# R7FA8M1AH register map
Vendor: Renesas; Series: RA8; File version: 1.2
CPU: CM85 r0p0, little endian, MPU, FPU, VTOR, 4 interrupt priority bits
Registers are 32-bit, read-write, reset 0x0 unless marked. A register's access mark holds for its fields unless they carry their own. Offsets are from the block's base; [hi:lo] are bit positions; 'fields as' and 'values as' point back to an identical list.

## I3C (part 2 of 4) — I2C I3C unified IP
Base 0x4035F000
Same registers: I3C_NS 0x5035F000
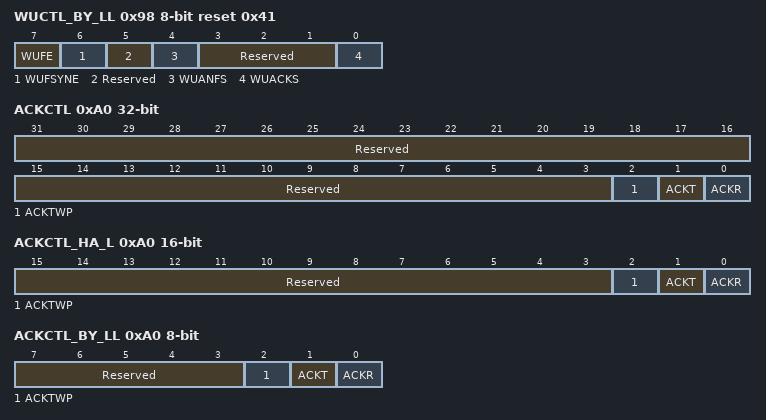
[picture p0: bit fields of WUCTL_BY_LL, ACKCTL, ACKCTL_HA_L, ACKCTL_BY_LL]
0x98 WUCTL_BY_LL 8-bit reset 0x41 — Wake Up Unit Control Register
  [7] WUFE — Wake Up function Enable
    0=Wake-up function disables; 1=Wake-up function enables
  [6] WUFSYNE — Wake-Up function Synchronous Enable
    0=This IP asynchronous circuit enable; 1=This IP synchronous circuit enable
  [5] Reserved — This bit is read as 0. The write value should be 0.
  [4] WUANFS — Wake-Up Analog Noise Filter Selection
    0=Do not add the Wake Up analog filter; 1=Add the Wake Up analog filter
  [3:1] Reserved — These bits are read as 000. The write value should be 000.
  [0] WUACKS — Wake-Up Acknowledge Selection
0xA0 ACKCTL — Acknowledge Control Register
  [31:3] Reserved — These bits are read as 00000000000000000000000000000. The write value should be 00000000000000000000000000000.
  [2] ACKTWP wo — ACKT Write Protect
    0=The ACKT bit are protected; 1=The ACKT bit can be written (When writing simultaneously with the value of the target bit)
  [1] ACKT read-modifies — Acknowledge Transmission
    0=A 0 is sent as the acknowledge bit (ACK transmission); 1=A 1 is sent as the acknowledge bit (NACK transmission)
  [0] ACKR ro — Acknowledge Reception
    0=A 0 is received as the acknowledge bit (ACK reception); 1=A 1 is received as the acknowledge bit (NACK reception)
0xA0 ACKCTL_HA_L 16-bit — Acknowledge Control Register
  [15:3] Reserved — These bits are read as 0000000000000. The write value should be 0000000000000.
  [2] ACKTWP wo — ACKT Write Protect
    values as ACKCTL.ACKTWP
  [1] ACKT read-modifies — Acknowledge Transmission
    values as ACKCTL.ACKT
  [0] ACKR ro — Acknowledge Reception
    values as ACKCTL.ACKR
0xA0 ACKCTL_BY_LL 8-bit — Acknowledge Control Register
  [7:3] Reserved — These bits are read as 00000. The write value should be 00000.
  [2] ACKTWP wo — ACKT Write Protect
    values as ACKCTL.ACKTWP
  [1] ACKT read-modifies — Acknowledge Transmission
    values as ACKCTL.ACKT
  [0] ACKR ro — Acknowledge Reception
    values as ACKCTL.ACKR
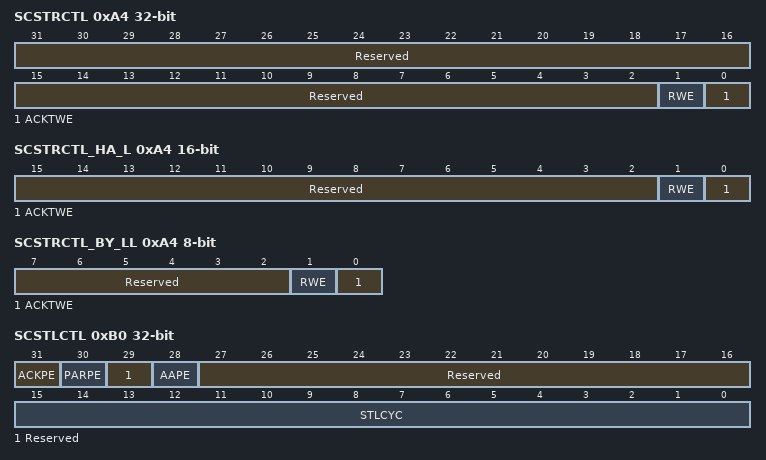
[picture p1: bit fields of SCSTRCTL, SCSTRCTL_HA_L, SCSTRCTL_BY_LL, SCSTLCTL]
0xA4 SCSTRCTL — SCL Stretch Control Register
  [31:2] Reserved — These bits are read as 000000000000000000000000000000. The write value should be 000000000000000000000000000000.
  [1] RWE — Receive Wait Enable
    0=No WAIT (The period between ninth clock cycle and first clock cycle is not held low.); 1=WAIT (The period between ninth clock cycle and first clock cycle is held low.)
  [0] ACKTWE — Acknowledge Transmission Wait Enabl (*1)
    0=NTST.RDBFF0 is set at the rising edge of the ninth SCL clock cycle; 1=NTST.RDBFF0 is set at the rising edge of the eighth SCL clock cycle
0xA4 SCSTRCTL_HA_L 16-bit — SCL Stretch Control Register
  [15:2] Reserved — These bits are read as 00000000000000. The write value should be 00000000000000.
  [1] RWE — Receive Wait Enable
    values as SCSTRCTL.RWE
  [0] ACKTWE — Acknowledge Transmission Wait Enabl (*1)
    values as SCSTRCTL.ACKTWE
0xA4 SCSTRCTL_BY_LL 8-bit — SCL Stretch Control Register
  [7:2] Reserved — These bits are read as 000000. The write value should be 000000.
  [1] RWE — Receive Wait Enable
    values as SCSTRCTL.RWE
  [0] ACKTWE — Acknowledge Transmission Wait Enabl (*1)
    values as SCSTRCTL.ACKTWE
0xB0 SCSTLCTL — SCL Stalling Control Register
  [31] ACKPE — ACK phase EnableStall enable bit during ACK/NACK phase
    0=Does not stall the SCL clock during the ACK/NACK phase; 1=Stall the SCL clock during the ACK/NACK phase
  [30] PARPE — Parity Phase EnableStall enable bit in parity bit period
    0=Does not stall the SCL clock during the parity bit period; 1=Stall the SCL clock during the parity bit period
  [29] Reserved — This bit is read as 0. The write value should be 0.
  [28] AAPE — Assigend Address Phase EnableEnable bit that allows stall by the first bit at address assignment
    0=Does not stall the SCL clock during the address assignment phase; 1=Stall the SCL clock during the parity bit period address assignment phase
  [27:16] Reserved — These bits are read as 000000000000. The write value should be 000000000000.
  [15:0] STLCYC — Stalling Cycle
0xB0 SCSTLCTL_HA_L 16-bit — SCL Stalling Control Register
  [15:0] STLCYC — Stalling Cycle
0xB0 SCSTLCTL_BY_LL 8-bit — SCL Stalling Control Register
  [7:0] STLCYC — Stalling Cycle
0xB1 SCSTLCTL_BY_LH 8-bit — SCL Stalling Control Register
  [7:0] STLCYC — Stalling Cycle
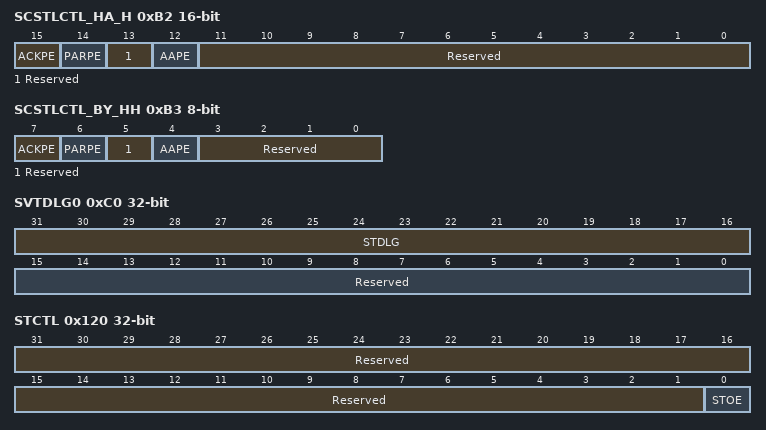
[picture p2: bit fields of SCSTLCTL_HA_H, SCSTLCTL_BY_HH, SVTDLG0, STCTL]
0xB2 SCSTLCTL_HA_H 16-bit — SCL Stalling Control Register
  [15] ACKPE — ACK phase EnableStall enable bit during ACK/NACK phase
    values as SCSTLCTL.ACKPE
  [14] PARPE — Parity Phase EnableStall enable bit in parity bit period
    values as SCSTLCTL.PARPE
  [13] Reserved — This bit is read as 0. The write value should be 0.
  [12] AAPE — Assigend Address Phase EnableEnable bit that allows stall by the first bit at address assignment
    values as SCSTLCTL.AAPE
  [11:0] Reserved — These bits are read as 000000000000. The write value should be 000000000000.
0xB3 SCSTLCTL_BY_HH 8-bit — SCL Stalling Control Register
  [7] ACKPE — ACK phase EnableStall enable bit during ACK/NACK phase
    values as SCSTLCTL.ACKPE
  [6] PARPE — Parity Phase EnableStall enable bit in parity bit period
    values as SCSTLCTL.PARPE
  [5] Reserved — This bit is read as 0. The write value should be 0.
  [4] AAPE — Assigend Address Phase EnableEnable bit that allows stall by the first bit at address assignment
    values as SCSTLCTL.AAPE
  [3:0] Reserved — These bits are read as 0000. The write value should be 0000.
0xC0 SVTDLG0 — Slave Transfer Data Length Register 0
  [31:16] STDLG — Slave Transfer Data Length
  [15:0] Reserved — These bits are read as 0000000000000000. The write value should be 0000000000000000.
0xC2 SVTDLG0_HA_H 16-bit — Slave Transfer Data Length Register 0
  [15:0] STDLG — Slave Transfer Data Length
0xC2 SVTDLG0_BY_HL 8-bit — Slave Transfer Data Length Register 0
  [7:0] STDLG — Slave Transfer Data Length
0xC3 SVTDLG0_BY_HH 8-bit — Slave Transfer Data Length Register 0
  [7:0] STDLG — Slave Transfer Data Length
0x120 STCTL read-modifies — Synchronous Timiming Control Register
  [31:1] Reserved — These bits are read as 0000000000000000000000000000000. The write value should be 0000000000000000000000000000000.
  [0] STOE read-modifies — Synchronous Timing output Enable
    0=Disable; 1=Enable
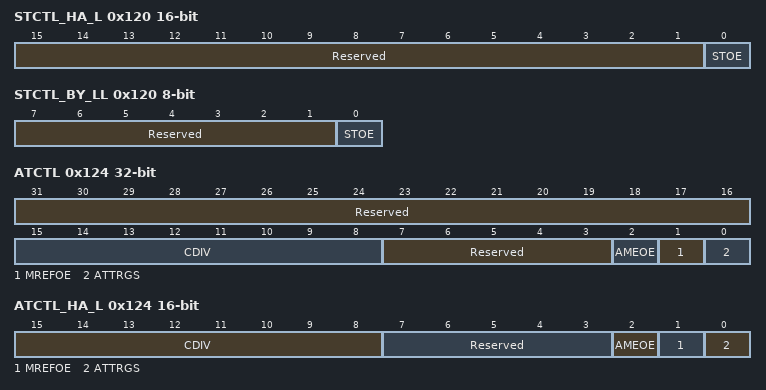
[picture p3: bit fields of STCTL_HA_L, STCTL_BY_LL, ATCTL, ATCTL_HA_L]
0x120 STCTL_HA_L 16-bit read-modifies — Synchronous Timiming Control Register
  [15:1] Reserved — These bits are read as 000000000000000. The write value should be 000000000000000.
  [0] STOE read-modifies — Synchronous Timing output Enable
    0=Disable; 1=Enable
0x120 STCTL_BY_LL 8-bit read-modifies — Synchronous Timiming Control Register
  [7:1] Reserved — These bits are read as 0000000. The write value should be 0000000.
  [0] STOE read-modifies — Synchronous Timing output Enable
    0=Disable; 1=Enable
0x124 ATCTL — Asynchronous Timimg Control Register
  [31:16] Reserved — These bits are read as 0000000000000000. The write value should be 0000000000000000.
  [15:8] CDIV — TCLK Counter Divide Setting
  [7:3] Reserved — These bits are read as 00000. The write value should be 00000.
  [2] AMEOE — Additional Master-initiated bus Event Output Enable
    0=Disable; 1=Enable
  [1] MREFOE — MREF Output Enable (Capture Event / Counter Overflow)
    0=Disable; 1=Enable
  [0] ATTRGS — Asynchronous Timing Trigger Select
    0=Software Trigger; 1=Hardware Trigger
0x124 ATCTL_HA_L 16-bit — Asynchronous Timimg Control Register
  [15:8] CDIV — TCLK Counter Divide Setting
  [7:3] Reserved — These bits are read as 00000. The write value should be 00000.
  [2] AMEOE — Additional Master-initiated bus Event Output Enable
    0=Disable; 1=Enable
  [1] MREFOE — MREF Output Enable (Capture Event / Counter Overflow)
    0=Disable; 1=Enable
  [0] ATTRGS — Asynchronous Timing Trigger Select
    0=Software Trigger; 1=Hardware Trigger
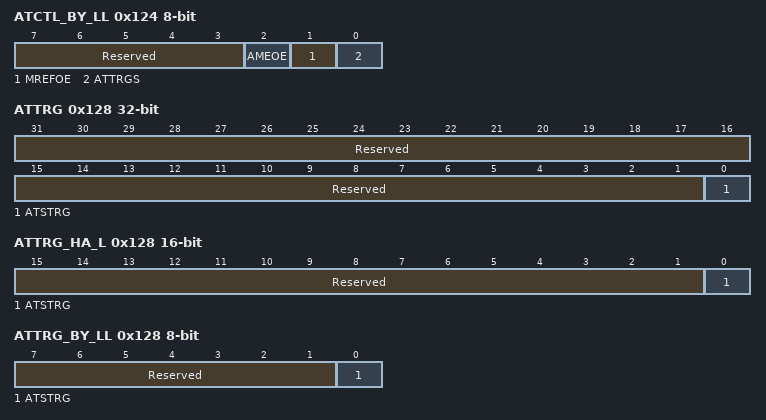
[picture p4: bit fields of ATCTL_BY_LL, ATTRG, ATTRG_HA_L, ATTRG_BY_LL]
0x124 ATCTL_BY_LL 8-bit — Asynchronous Timimg Control Register
  [7:3] Reserved — These bits are read as 00000. The write value should be 00000.
  [2] AMEOE — Additional Master-initiated bus Event Output Enable
    0=Disable; 1=Enable
  [1] MREFOE — MREF Output Enable (Capture Event / Counter Overflow)
    0=Disable; 1=Enable
  [0] ATTRGS — Asynchronous Timing Trigger Select
    0=Software Trigger; 1=Hardware Trigger
0x125 ATCTL_BY_LH 8-bit — Asynchronous Timimg Control Register
  [7:0] CDIV — TCLK Counter Divide Setting
0x128 ATTRG wo — Asynchronous Timiming Trigger Register
  [31:1] Reserved — The write value should be 0000000000000000000000000000000.
  [0] ATSTRG — Asynchronous Timing Software Trigger
    0=Write : do nothing; 1=Write : Software trigger (one-shot pulse) output
0x128 ATTRG_HA_L 16-bit wo — Asynchronous Timiming Trigger Register
  [15:1] Reserved — The write value should be 000000000000000.
  [0] ATSTRG — Asynchronous Timing Software Trigger
    values as ATTRG.ATSTRG
0x128 ATTRG_BY_LL 8-bit wo — Asynchronous Timiming Trigger Register
  [7:1] Reserved — The write value should be 0000000.
  [0] ATSTRG — Asynchronous Timing Software Trigger
    values as ATTRG.ATSTRG
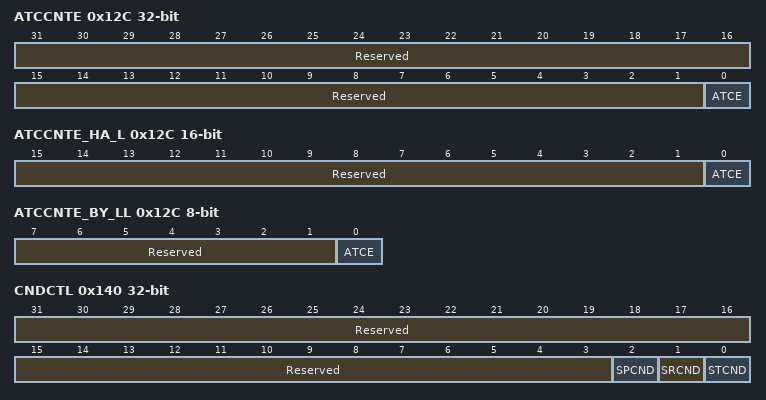
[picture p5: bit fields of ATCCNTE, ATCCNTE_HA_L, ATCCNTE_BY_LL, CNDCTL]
0x12C ATCCNTE — Asynchronous Timing Contorol Counter enable Register
  [31:1] Reserved — These bits are read as 0000000000000000000000000000000. The write value should be 0000000000000000000000000000000.
  [0] ATCE — Asynchronous Timing Counter Enable for MREF, MC2, SC1, SC2.
    0=Disable; 1=Enable
0x12C ATCCNTE_HA_L 16-bit — Asynchronous Timing Contorol Counter enable Register
  [15:1] Reserved — These bits are read as 000000000000000. The write value should be 000000000000000.
  [0] ATCE — Asynchronous Timing Counter Enable for MREF, MC2, SC1, SC2.
    0=Disable; 1=Enable
0x12C ATCCNTE_BY_LL 8-bit — Asynchronous Timing Contorol Counter enable Register
  [7:1] Reserved — These bits are read as 0000000. The write value should be 0000000.
  [0] ATCE — Asynchronous Timing Counter Enable for MREF, MC2, SC1, SC2.
    0=Disable; 1=Enable
0x140 CNDCTL — Condition Control Register
  [31:3] Reserved — These bits are read as 00000000000000000000000000000. The write value should be 00000000000000000000000000000.
  [2] SPCND read-modifies — STOP (P) Condition Issuance
    0=Does not request to issue a STOP condition; 1=Requests to issue a STOP condition
  [1] SRCND read-modifies — Repeated START (Sr) Condition Issuance
    0=Does not request to issue a Repeated START condition; 1=Requests to issue a Repeated START condition
  [0] STCND read-modifies — START (S) Condition Issuance
    0=Does not request to issue a START condition; 1=Requests to issue a START condition
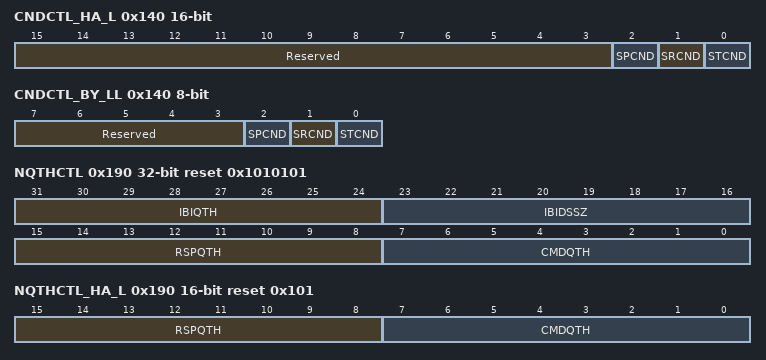
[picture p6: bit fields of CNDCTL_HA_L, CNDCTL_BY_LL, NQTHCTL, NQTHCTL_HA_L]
0x140 CNDCTL_HA_L 16-bit — Condition Control Register
  [15:3] Reserved — These bits are read as 0000000000000. The write value should be 0000000000000.
  [2] SPCND read-modifies — STOP (P) Condition Issuance
    values as CNDCTL.SPCND
  [1] SRCND read-modifies — Repeated START (Sr) Condition Issuance
    values as CNDCTL.SRCND
  [0] STCND read-modifies — START (S) Condition Issuance
    values as CNDCTL.STCND
0x140 CNDCTL_BY_LL 8-bit — Condition Control Register
  [7:3] Reserved — These bits are read as 00000. The write value should be 00000.
  [2] SPCND read-modifies — STOP (P) Condition Issuance
    values as CNDCTL.SPCND
  [1] SRCND read-modifies — Repeated START (Sr) Condition Issuance
    values as CNDCTL.SRCND
  [0] STCND read-modifies — START (S) Condition Issuance
    values as CNDCTL.STCND
0x150 NCMDQP wo — Normal Command Queue Port Register
  [31:0] NCMDQP — Normal Command Queue Port
0x154 NRSPQP ro read-modifies — Normal Response Queue Port Register
  [31:0] NRSPQP read-modifies — Normal Response Queue Port
0x158 NTDTBP0 read-modifies — Normal Transfer Data Buffer Port Register 0
  [31:0] NTDTBP0 read-modifies — Normal Transfer Data Buffer Port
0x158 NTDTBP0_BY_LL 8-bit read-modifies — Normal Transfer Data Buffer Port Register 0
  [7:0] NTDTBP0 read-modifies — Normal Transfer Data Buffer Port
0x17C NIBIQP read-modifies — Normal IBI Queue Port Register
  [31:0] NIBIQP read-modifies — Normal IBI Queue Port
0x180 NRSQP ro read-modifies — Normal Receive Status Queue Port Register
  [31:0] NRSQP read-modifies — Normal Receive Status Queue Port
0x184 HCMDQP wo — High Priority Command Queue Port Register
  [31:0] HCMDQP — High Priority Command Queue Port
0x188 HRSPQP ro read-modifies — High Priority Response Queue Port Register
  [31:0] HRSPQP read-modifies — High Priority Response Queue Port
0x18C HTDTBP read-modifies — High Priority Transfer Data Buffer Port Register
  [31:0] HTDTBP read-modifies — High Priority Transfer Data Buffer Port
0x190 NQTHCTL reset 0x1010101 — Normal Queue Threshold Control Register
  [31:24] IBIQTH — Normal IBI Queue Threshold
    0=Interrupt is generated when the Outstanding IBI Status count is >= 1; 0=Interrupt is issued when IBI Data Buffer is completely empty
  [23:16] IBIDSSZ — Normal IBI Data Segment Size
  [15:8] RSPQTH — Normal Response Queue Threshold
    0=Interrupt is issued when response Queue contains 1 entry (DWORD)
  [7:0] CMDQTH — Normal Command Queue Threshold
    0=Interrupt is issued when Command Queue is completely empty
0x190 NQTHCTL_HA_L 16-bit reset 0x101 — Normal Queue Threshold Control Register
  [15:8] RSPQTH — Normal Response Queue Threshold
    values as NQTHCTL.RSPQTH
  [7:0] CMDQTH — Normal Command Queue Threshold
    0=Interrupt is issued when Command Queue is completely empty
0x190 NQTHCTL_BY_LL 8-bit reset 0x1 — Normal Queue Threshold Control Register
  [7:0] CMDQTH — Normal Command Queue Threshold
    0=Interrupt is issued when Command Queue is completely empty
0x191 NQTHCTL_BY_LH 8-bit reset 0x1 — Normal Queue Threshold Control Register
  [7:0] RSPQTH — Normal Response Queue Threshold
    values as NQTHCTL.RSPQTH
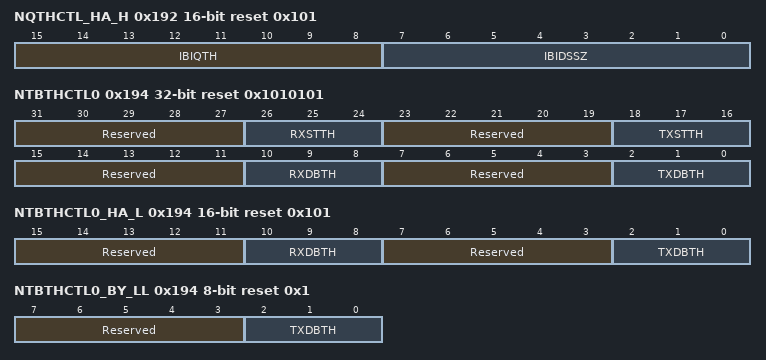
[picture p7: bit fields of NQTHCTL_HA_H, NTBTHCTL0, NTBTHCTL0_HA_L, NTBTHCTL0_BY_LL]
0x192 NQTHCTL_HA_H 16-bit reset 0x101 — Normal Queue Threshold Control Register
  [15:8] IBIQTH — Normal IBI Queue Threshold
    values as NQTHCTL.IBIQTH
  [7:0] IBIDSSZ — Normal IBI Data Segment Size
0x192 NQTHCTL_BY_HL 8-bit reset 0x1 — Normal Queue Threshold Control Register
  [7:0] IBIDSSZ — Normal IBI Data Segment Size
0x193 NQTHCTL_BY_HH 8-bit reset 0x1 — Normal Queue Threshold Control Register
  [7:0] IBIQTH — Normal IBI Queue Threshold
    values as NQTHCTL.IBIQTH
0x194 NTBTHCTL0 reset 0x1010101 — Normal Transfer Data Buffer Threshold Control Register 0
  [31:27] Reserved — These bits are read as 00000. The write value should be 00000.
  [26:24] RXSTTH — Normal Rx Start Threshold
    0=Wait for 2 empty DWORDs; 1=Wait for 4 empty DWORDs; 2=Wait for 8 empty DWORDs; 3=Wait for 16 empty DWORDs; 4=Wait for 32 empty DWORDs; 5=Wait for 64 empty DWORDs; 6=Wait for 128 empty DWORDs; 7=Wait for 256 empty DWORDs
  [23:19] Reserved — These bits are read as 00000. The write value should be 00000.
  [18:16] TXSTTH — Normal Tx Start Threshold
    0=Wait for 2 entry DWORDs; 1=Wait for 4 entry DWORDs; 2=Wait for 8 entry DWORDs; 3=Wait for 16 entry DWORDs; 4=Wait for 32 entry DWORDs; 5=Wait for 64 entry DWORDs; 6=Wait for 128 entry DWORDs; 7=Wait for 256 entry DWORDs
  [15:11] Reserved — These bits are read as 00000. The write value should be 00000.
  [10:8] RXDBTH — Normal Rx Data Buffer Threshold
    0=Interrupt triggers at 2 Rx Buffer entries, DWORDs; 1=Interrupt triggers at 4 Rx Buffer entries, DWORDs; 2=Interrupt triggers at 8 Rx Buffer entries, DWORDs; 3=Interrupt triggers at 16 Rx Buffer entries, DWORDs; 4=Interrupt triggers at 32 Rx Buffer entries, DWORDs; 5=Interrupt triggers at 64 Rx Buffer entries, DWORDs; 6=Interrupt triggers at 128 Rx Buffer entries, DWORDs; 7=Interrupt triggers at 256 Rx Buffer entries, DWORDs
  [7:3] Reserved — These bits are read as 00000. The write value should be 00000.
  [2:0] TXDBTH — Normal Tx Data Buffer Threshold
    0=Interrupt triggers at 2 Tx Buffer entries, DWORDs; 1=Interrupt triggers at 4 Tx Buffer entries, DWORDs; 2=Interrupt triggers at 8 Tx Buffer entries, DWORDs; 3=Interrupt triggers at 16 Tx Buffer entries, DWORDs; 4=Interrupt triggers at 32 Tx Buffer entries, DWORDs; 5=Interrupt triggers at 64 Tx Buffer entries, DWORDs; 6=Interrupt triggers at 128 Tx Buffer entries, DWORDs; 7=Interrupt triggers at 256 Tx Buffer entries, DWORDs
0x194 NTBTHCTL0_HA_L 16-bit reset 0x101 — Normal Transfer Data Buffer Threshold Control Register 0
  [15:11] Reserved — These bits are read as 00000. The write value should be 00000.
  [10:8] RXDBTH — Normal Rx Data Buffer Threshold
    values as NTBTHCTL0.RXDBTH
  [7:3] Reserved — These bits are read as 00000. The write value should be 00000.
  [2:0] TXDBTH — Normal Tx Data Buffer Threshold
    values as NTBTHCTL0.TXDBTH
0x194 NTBTHCTL0_BY_LL 8-bit reset 0x1 — Normal Transfer Data Buffer Threshold Control Register 0
  [7:3] Reserved — These bits are read as 00000. The write value should be 00000.
  [2:0] TXDBTH — Normal Tx Data Buffer Threshold
    values as NTBTHCTL0.TXDBTH
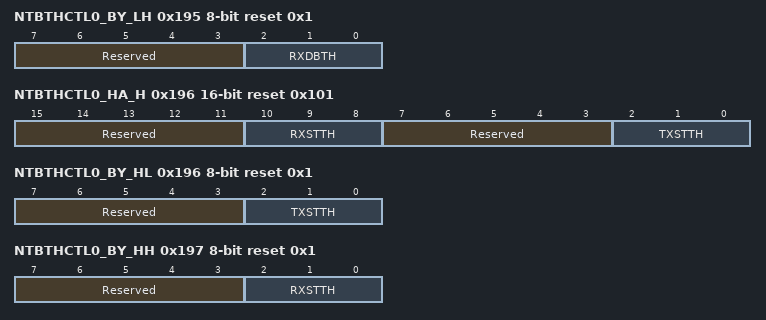
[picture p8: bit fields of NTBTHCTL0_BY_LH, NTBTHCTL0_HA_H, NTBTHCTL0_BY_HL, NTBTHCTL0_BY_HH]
0x195 NTBTHCTL0_BY_LH 8-bit reset 0x1 — Normal Transfer Data Buffer Threshold Control Register 0
  [7:3] Reserved — These bits are read as 00000. The write value should be 00000.
  [2:0] RXDBTH — Normal Rx Data Buffer Threshold
    values as NTBTHCTL0.RXDBTH
0x196 NTBTHCTL0_HA_H 16-bit reset 0x101 — Normal Transfer Data Buffer Threshold Control Register 0
  [15:11] Reserved — These bits are read as 00000. The write value should be 00000.
  [10:8] RXSTTH — Normal Rx Start Threshold
    values as NTBTHCTL0.RXSTTH
  [7:3] Reserved — These bits are read as 00000. The write value should be 00000.
  [2:0] TXSTTH — Normal Tx Start Threshold
    values as NTBTHCTL0.TXSTTH
0x196 NTBTHCTL0_BY_HL 8-bit reset 0x1 — Normal Transfer Data Buffer Threshold Control Register 0
  [7:3] Reserved — These bits are read as 00000. The write value should be 00000.
  [2:0] TXSTTH — Normal Tx Start Threshold
    values as NTBTHCTL0.TXSTTH
0x197 NTBTHCTL0_BY_HH 8-bit reset 0x1 — Normal Transfer Data Buffer Threshold Control Register 0
  [7:3] Reserved — These bits are read as 00000. The write value should be 00000.
  [2:0] RXSTTH — Normal Rx Start Threshold
    values as NTBTHCTL0.RXSTTH
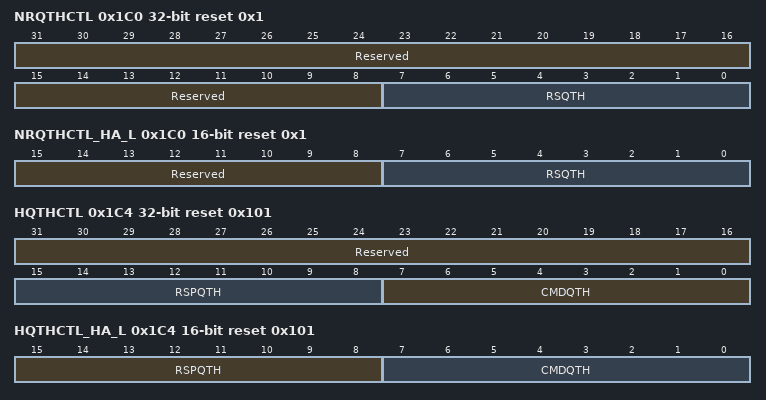
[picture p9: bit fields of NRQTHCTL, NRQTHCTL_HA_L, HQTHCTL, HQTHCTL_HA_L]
0x1C0 NRQTHCTL reset 0x1 — Normal Receive Status Queue Threshold Control Register
  [31:8] Reserved — These bits are read as 000000000000000000000000. The write value should be 000000000000000000000000.
  [7:0] RSQTH — Normal Receive Status Queue Threshold
    0=Interrupt is issued when Receive Status Queue contains 1 entry (DWORD)
0x1C0 NRQTHCTL_HA_L 16-bit reset 0x1 — Normal Receive Status Queue Threshold Control Register
  [15:8] Reserved — These bits are read as 00000000. The write value should be 00000000.
  [7:0] RSQTH — Normal Receive Status Queue Threshold
    values as NRQTHCTL.RSQTH
0x1C0 NRQTHCTL_BY_LL 8-bit reset 0x1 — Normal Receive Status Queue Threshold Control Register
  [7:0] RSQTH — Normal Receive Status Queue Threshold
    values as NRQTHCTL.RSQTH
0x1C4 HQTHCTL reset 0x101 — High Priority Queue Threshold Control Register
  [31:16] Reserved — These bits are read as 0000000000000000. The write value should be 0000000000000000.
  [15:8] RSPQTH — High Priority Response Queue Threshold
    0=Interrupt is issued when High Priority Response Queue contains 1 entry (DWORD)
  [7:0] CMDQTH — High Priority Command Queue Threshold
    0=Interrupt is issued when High Priority Command Queue is completely empty
0x1C4 HQTHCTL_HA_L 16-bit reset 0x101 — High Priority Queue Threshold Control Register
  [15:8] RSPQTH — High Priority Response Queue Threshold
    values as HQTHCTL.RSPQTH
  [7:0] CMDQTH — High Priority Command Queue Threshold
    values as HQTHCTL.CMDQTH
0x1C4 HQTHCTL_BY_LL 8-bit reset 0x1 — High Priority Queue Threshold Control Register
  [7:0] CMDQTH — High Priority Command Queue Threshold
    values as HQTHCTL.CMDQTH
0x1C5 HQTHCTL_BY_LH 8-bit reset 0x1 — High Priority Queue Threshold Control Register
  [7:0] RSPQTH — High Priority Response Queue Threshold
    values as HQTHCTL.RSPQTH
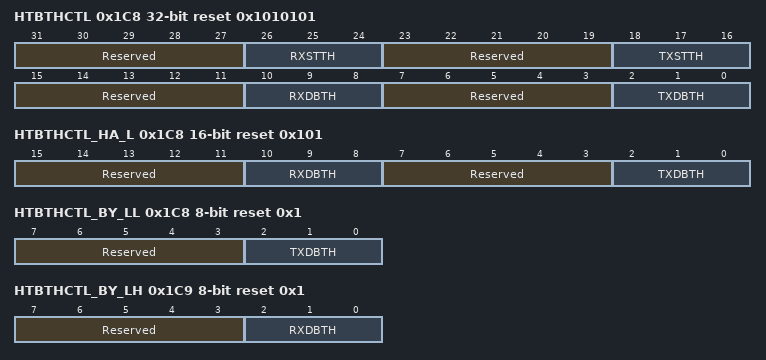
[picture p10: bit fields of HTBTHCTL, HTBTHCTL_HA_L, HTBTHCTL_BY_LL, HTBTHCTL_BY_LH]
0x1C8 HTBTHCTL reset 0x1010101 — High Priority Transfer Data Buffer Threshold Control Register
  [31:27] Reserved — These bits are read as 00000. The write value should be 00000.
  [26:24] RXSTTH — High Priority Rx Start Threshold
    values as NTBTHCTL0.RXSTTH
  [23:19] Reserved — These bits are read as 00000. The write value should be 00000.
  [18:16] TXSTTH — High Priority Tx Start Threshold
    values as NTBTHCTL0.TXSTTH
  [15:11] Reserved — These bits are read as 00000. The write value should be 00000.
  [10:8] RXDBTH — High Priority Rx Data Buffer Threshold
    0=Interrupt triggers at 2 High Priority Rx Buffer entries, DWORDs; 1=Interrupt triggers at 4 High Priority Rx Buffer entries, DWORDs; 2=Interrupt triggers at 8 High Priority Rx Buffer entries, DWORDs; 3=Interrupt triggers at 16 High Priority Rx Buffer entries, DWORDs; 4=Interrupt triggers at 32 High Priority Rx Buffer entries, DWORDs; 5=Interrupt triggers at 64 High Priority Rx Buffer entries, DWORDs; 6=Interrupt triggers at 128 High Priority Rx Buffer entries, DWORDs; 7=Interrupt triggers at 256 High Priority Rx Buffer entries, DWORDs
  [7:3] Reserved — These bits are read as 00000. The write value should be 00000.
  [2:0] TXDBTH — High Priority Tx Data Buffer Threshold
    0=Interrupt triggers at 2 High Priority Tx Buffer empties, DWORDs; 1=Interrupt triggers at 4 High Priority Tx Buffer empties, DWORDs; 2=Interrupt triggers at 8 High Priority Tx Buffer empties, DWORDs; 3=Interrupt triggers at 16 High Priority Tx Buffer empties, DWORDs; 4=Interrupt triggers at 32 High Priority Tx Buffer empties, DWORDs; 5=Interrupt triggers at 64 High Priority Tx Buffer empties, DWORDs; 6=Interrupt triggers at 128 High Priority Tx Buffer empties, DWORDs; 7=Interrupt triggers at 256 High Priority Tx Buffer empties, DWORDs
0x1C8 HTBTHCTL_HA_L 16-bit reset 0x101 — High Priority Transfer Data Buffer Threshold Control Register
  [15:11] Reserved — These bits are read as 00000. The write value should be 00000.
  [10:8] RXDBTH — High Priority Rx Data Buffer Threshold
    values as HTBTHCTL.RXDBTH
  [7:3] Reserved — These bits are read as 00000. The write value should be 00000.
  [2:0] TXDBTH — High Priority Tx Data Buffer Threshold
    values as HTBTHCTL.TXDBTH
0x1C8 HTBTHCTL_BY_LL 8-bit reset 0x1 — High Priority Transfer Data Buffer Threshold Control Register
  [7:3] Reserved — These bits are read as 00000. The write value should be 00000.
  [2:0] TXDBTH — High Priority Tx Data Buffer Threshold
    values as HTBTHCTL.TXDBTH
0x1C9 HTBTHCTL_BY_LH 8-bit reset 0x1 — High Priority Transfer Data Buffer Threshold Control Register
  [7:3] Reserved — These bits are read as 00000. The write value should be 00000.
  [2:0] RXDBTH — High Priority Rx Data Buffer Threshold
    values as HTBTHCTL.RXDBTH
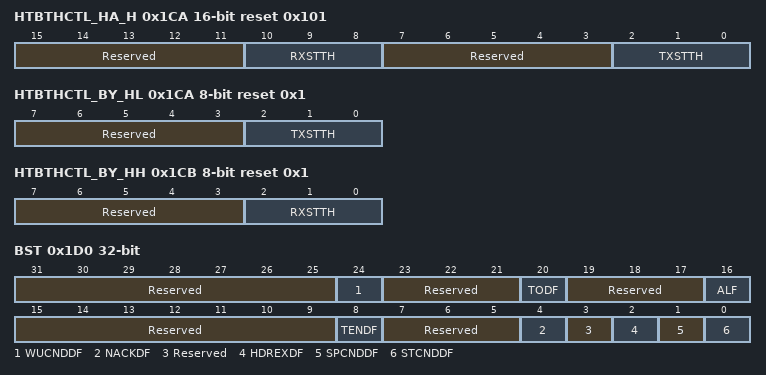
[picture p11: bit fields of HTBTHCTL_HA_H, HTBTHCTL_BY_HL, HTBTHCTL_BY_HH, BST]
0x1CA HTBTHCTL_HA_H 16-bit reset 0x101 — High Priority Transfer Data Buffer Threshold Control Register
  [15:11] Reserved — These bits are read as 00000. The write value should be 00000.
  [10:8] RXSTTH — High Priority Rx Start Threshold
    values as NTBTHCTL0.RXSTTH
  [7:3] Reserved — These bits are read as 00000. The write value should be 00000.
  [2:0] TXSTTH — High Priority Tx Start Threshold
    values as NTBTHCTL0.TXSTTH
0x1CA HTBTHCTL_BY_HL 8-bit reset 0x1 — High Priority Transfer Data Buffer Threshold Control Register
  [7:3] Reserved — These bits are read as 00000. The write value should be 00000.
  [2:0] TXSTTH — High Priority Tx Start Threshold
    values as NTBTHCTL0.TXSTTH
0x1CB HTBTHCTL_BY_HH 8-bit reset 0x1 — High Priority Transfer Data Buffer Threshold Control Register
  [7:3] Reserved — These bits are read as 00000. The write value should be 00000.
  [2:0] RXSTTH — High Priority Rx Start Threshold
    values as NTBTHCTL0.RXSTTH
0x1D0 BST read-modifies — Bus Status Register
  [31:25] Reserved — These bits are read as 0000000. The write value should be 0000000.
  [24] WUCNDDF read-modifies — Wake-Up Condition Detection Flag
    0=Wake-Up Condition is not detected; 1=Wake-Up Condition is detected
  [23:21] Reserved — These bits are read as 000. The write value should be 000.
  [20] TODF read-modifies — Timeout Detection Flag
    0=Timeout is not detected; 1=Timeout is detected
  [19:17] Reserved — These bits are read as 000. The write value should be 000.
  [16] ALF read-modifies — Arbitration Lost Flag
    0=Arbitration is not lost; 1=Arbitration is lost
  [15:9] Reserved — These bits are read as 0000000. The write value should be 0000000.
  [8] TENDF read-modifies — Transmit End Flag
    0=Data is being transmitted; 1=Data has been transmitted
  [7:5] Reserved — These bits are read as 000. The write value should be 000.
  [4] NACKDF read-modifies — NACK Detection Flag
    0=NACK is not detected; 1=NACK is detected
  [3] Reserved — This bit is read as 0. The write value should be 0.
  [2] HDREXDF read-modifies — HDR Exit Pattern Detection Flag
    0=HDR Exit Pattern is not detected; 1=HDR Exit Pattern is detected
  [1] SPCNDDF read-modifies — STOP Condition Detection Flag
    0=STOP condition is not detected; 1=STOP condition is detected
  [0] STCNDDF read-modifies — START Condition Detection Flag
    0=START condition is not detected; 1=START condition is detected
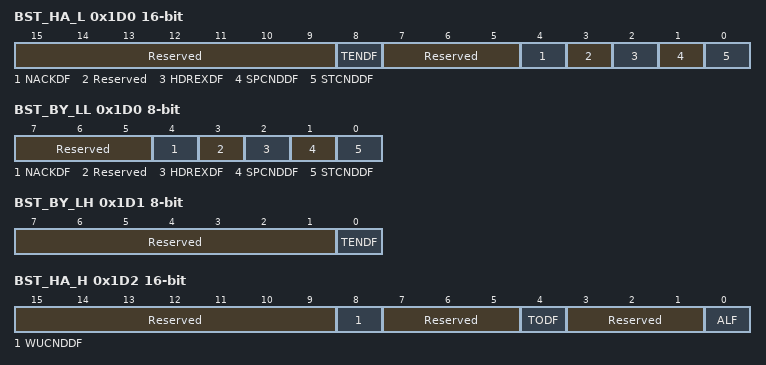
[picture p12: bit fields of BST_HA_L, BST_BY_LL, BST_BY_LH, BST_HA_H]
0x1D0 BST_HA_L 16-bit read-modifies — Bus Status Register
  [15:9] Reserved — These bits are read as 0000000. The write value should be 0000000.
  [8] TENDF read-modifies — Transmit End Flag
    0=Data is being transmitted; 1=Data has been transmitted
  [7:5] Reserved — These bits are read as 000. The write value should be 000.
  [4] NACKDF read-modifies — NACK Detection Flag
    0=NACK is not detected; 1=NACK is detected
  [3] Reserved — This bit is read as 0. The write value should be 0.
  [2] HDREXDF read-modifies — HDR Exit Pattern Detection Flag
    values as BST.HDREXDF
  [1] SPCNDDF read-modifies — STOP Condition Detection Flag
    values as BST.SPCNDDF
  [0] STCNDDF read-modifies — START Condition Detection Flag
    values as BST.STCNDDF
0x1D0 BST_BY_LL 8-bit read-modifies — Bus Status Register
  [7:5] Reserved — These bits are read as 000. The write value should be 000.
  [4] NACKDF read-modifies — NACK Detection Flag
    0=NACK is not detected; 1=NACK is detected
  [3] Reserved — This bit is read as 0. The write value should be 0.
  [2] HDREXDF read-modifies — HDR Exit Pattern Detection Flag
    values as BST.HDREXDF
  [1] SPCNDDF read-modifies — STOP Condition Detection Flag
    values as BST.SPCNDDF
  [0] STCNDDF read-modifies — START Condition Detection Flag
    values as BST.STCNDDF
0x1D1 BST_BY_LH 8-bit read-modifies — Bus Status Register
  [7:1] Reserved — These bits are read as 0000000. The write value should be 0000000.
  [0] TENDF read-modifies — Transmit End Flag
    0=Data is being transmitted; 1=Data has been transmitted
0x1D2 BST_HA_H 16-bit read-modifies — Bus Status Register
  [15:9] Reserved — These bits are read as 0000000. The write value should be 0000000.
  [8] WUCNDDF read-modifies — Wake-Up Condition Detection Flag
    values as BST.WUCNDDF
  [7:5] Reserved — These bits are read as 000. The write value should be 000.
  [4] TODF read-modifies — Timeout Detection Flag
    0=Timeout is not detected; 1=Timeout is detected
  [3:1] Reserved — These bits are read as 000. The write value should be 000.
  [0] ALF read-modifies — Arbitration Lost Flag
    0=Arbitration is not lost; 1=Arbitration is lost
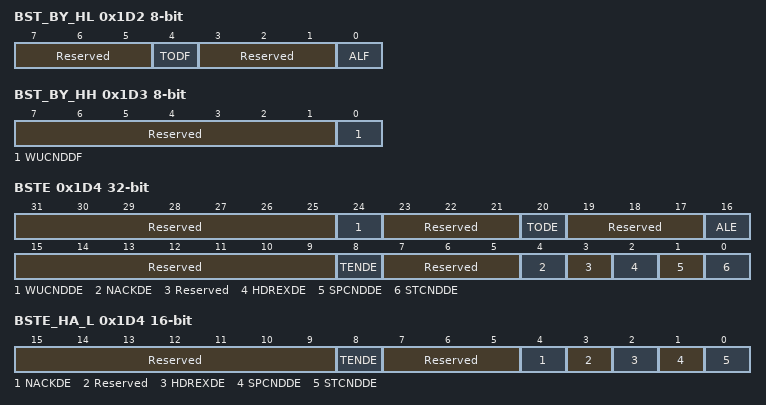
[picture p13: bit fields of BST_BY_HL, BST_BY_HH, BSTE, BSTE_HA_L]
0x1D2 BST_BY_HL 8-bit read-modifies — Bus Status Register
  [7:5] Reserved — These bits are read as 000. The write value should be 000.
  [4] TODF read-modifies — Timeout Detection Flag
    0=Timeout is not detected; 1=Timeout is detected
  [3:1] Reserved — These bits are read as 000. The write value should be 000.
  [0] ALF read-modifies — Arbitration Lost Flag
    0=Arbitration is not lost; 1=Arbitration is lost
0x1D3 BST_BY_HH 8-bit read-modifies — Bus Status Register
  [7:1] Reserved — These bits are read as 0000000. The write value should be 0000000.
  [0] WUCNDDF read-modifies — Wake-Up Condition Detection Flag
    values as BST.WUCNDDF
0x1D4 BSTE — Bus Status Enable Register
  [31:25] Reserved — These bits are read as 0000000. The write value should be 0000000.
  [24] WUCNDDE — Wake-up Condition Detection Enable
    0=Disables Wake-up Condition Detection Status logging; 1=Enables Wake-up Condition Detection Status logging
  [23:21] Reserved — These bits are read as 000. The write value should be 000.
  [20] TODE — Timeout Detection Enable
    0=Disables Timeout Detection Interrupt Status logging; 1=Enables Timeout Detection Interrupt Status logging
  [19:17] Reserved — These bits are read as 000. The write value should be 000.
  [16] ALE — Arbitration Lost Enable
    0=Disables Arbitration Lost Interrupt Status logging; 1=Enables Arbitration Lost Interrupt Status logging
  [15:9] Reserved — These bits are read as 0000000. The write value should be 0000000.
  [8] TENDE — Transmit End Enable
    0=Disables Transmit End Interrupt Status logging; 1=Enables Transmit End Interrupt Status logging
  [7:5] Reserved — These bits are read as 000. The write value should be 000.
  [4] NACKDE — NACK Detection Enable
    0=Disables NACK Detection Interrupt Status logging; 1=Enables NACK Detection Interrupt Status logging
  [3] Reserved — This bit is read as 0. The write value should be 0.
  [2] HDREXDE — HDR Exit Pattern Detection Enable
    0=Disables HDR Exit Pattern Detection Interrupt Status logging; 1=Enables HDR Exit Pattern Detection Interrupt Status logging
  [1] SPCNDDE — STOP Condition Detection Enable
    0=Disables STOP Condition Detection Interrupt Status logging; 1=Enables STOP Condition Detection Interrupt Status logging
  [0] STCNDDE — START Condition Detection Enable
    0=Disables START Condition Detection Interrupt Status logging; 1=Enables START Condition Detection Interrupt Status logging
0x1D4 BSTE_HA_L 16-bit — Bus Status Enable Register
  [15:9] Reserved — These bits are read as 0000000. The write value should be 0000000.
  [8] TENDE — Transmit End Enable
    values as BSTE.TENDE
  [7:5] Reserved — These bits are read as 000. The write value should be 000.
  [4] NACKDE — NACK Detection Enable
    values as BSTE.NACKDE
  [3] Reserved — This bit is read as 0. The write value should be 0.
  [2] HDREXDE — HDR Exit Pattern Detection Enable
    values as BSTE.HDREXDE
  [1] SPCNDDE — STOP Condition Detection Enable
    values as BSTE.SPCNDDE
  [0] STCNDDE — START Condition Detection Enable
    values as BSTE.STCNDDE
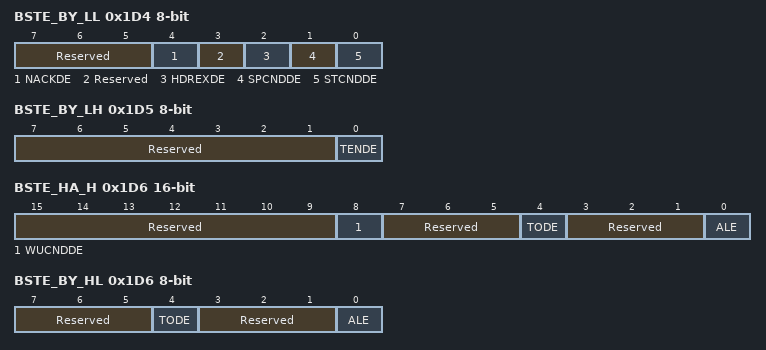
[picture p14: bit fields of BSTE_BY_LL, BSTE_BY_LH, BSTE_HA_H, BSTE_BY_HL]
0x1D4 BSTE_BY_LL 8-bit — Bus Status Enable Register
  [7:5] Reserved — These bits are read as 000. The write value should be 000.
  [4] NACKDE — NACK Detection Enable
    values as BSTE.NACKDE
  [3] Reserved — This bit is read as 0. The write value should be 0.
  [2] HDREXDE — HDR Exit Pattern Detection Enable
    values as BSTE.HDREXDE
  [1] SPCNDDE — STOP Condition Detection Enable
    values as BSTE.SPCNDDE
  [0] STCNDDE — START Condition Detection Enable
    values as BSTE.STCNDDE
0x1D5 BSTE_BY_LH 8-bit — Bus Status Enable Register
  [7:1] Reserved — These bits are read as 0000000. The write value should be 0000000.
  [0] TENDE — Transmit End Enable
    values as BSTE.TENDE
0x1D6 BSTE_HA_H 16-bit — Bus Status Enable Register
  [15:9] Reserved — These bits are read as 0000000. The write value should be 0000000.
  [8] WUCNDDE — Wake-up Condition Detection Enable
    values as BSTE.WUCNDDE
  [7:5] Reserved — These bits are read as 000. The write value should be 000.
  [4] TODE — Timeout Detection Enable
    values as BSTE.TODE
  [3:1] Reserved — These bits are read as 000. The write value should be 000.
  [0] ALE — Arbitration Lost Enable
    values as BSTE.ALE
0x1D6 BSTE_BY_HL 8-bit — Bus Status Enable Register
  [7:5] Reserved — These bits are read as 000. The write value should be 000.
  [4] TODE — Timeout Detection Enable
    values as BSTE.TODE
  [3:1] Reserved — These bits are read as 000. The write value should be 000.
  [0] ALE — Arbitration Lost Enable
    values as BSTE.ALE
0x1D7 BSTE_BY_HH 8-bit — Bus Status Enable Register
  [7:1] Reserved — These bits are read as 0000000. The write value should be 0000000.
  [0] WUCNDDE — Wake-up Condition Detection Enable
    values as BSTE.WUCNDDE
0x1D8 BIE — Bus Interrupt Enable Register
  [31:25] Reserved — These bits are read as 0000000. The write value should be 0000000.
  [24] WUCNDDIE — Wake-Up Condition Detection Interrupt Enable
    0=Disables Wake-Up Condition Detection Interrupt Signal; 1=Enables Wake-Up Condition Detection Interrupt Signal
  [23:21] Reserved — These bits are read as 000. The write value should be 000.
  [20] TODIE — Timeout Detection Interrupt Enable
    0=Disables Timeout Detection Interrupt Signal; 1=Enables Timeout Detection Interrupt Signal
  [19:17] Reserved — These bits are read as 000. The write value should be 000.
  [16] ALIE — Arbitration Lost Interrupt Enable
    0=Disables Arbitration Lost Interrupt Signal; 1=Enables Arbitration Lost Interrupt Signal
  [15:9] Reserved — These bits are read as 0000000. The write value should be 0000000.
  [8] TENDIE — Transmit End Interrupt Enable
    0=Disables Transmit End Interrupt Signal; 1=Enables Transmit End Interrupt Signal
  [7:5] Reserved — These bits are read as 000. The write value should be 000.
  [4] NACKDIE — NACK Detection Interrupt Enable
    0=Disables NACK Detection Interrupt Signal; 1=Enables NACK Detection Interrupt Signal
  [3] Reserved — This bit is read as 0. The write value should be 0.
  [2] HDREXDIE — HDR Exit Pattern Detection Interrupt Enable
    0=Disables HDR Exit Pattern Detection Interrupt Signal; 1=Enables HDR Exit Pattern Detection Interrupt Signal
  [1] SPCNDDIE — STOP Condition Detection Interrupt Enable
    0=Disables STOP Condition Detection Interrupt Signal; 1=Enables STOP Condition Detection Interrupt Signal
  [0] STCNDDIE — START Condition Detection Interrupt Enable
    0=Disables START Condition Detection Interrupt Signal; 1=Enables START Condition Detection Interrupt Signal
0x1D8 BIE_HA_L 16-bit — Bus Interrupt Enable Register
  [15:9] Reserved — These bits are read as 0000000. The write value should be 0000000.
  [8] TENDIE — Transmit End Interrupt Enable
    values as BIE.TENDIE
  [7:5] Reserved — These bits are read as 000. The write value should be 000.
  [4] NACKDIE — NACK Detection Interrupt Enable
    values as BIE.NACKDIE
  [3] Reserved — This bit is read as 0. The write value should be 0.
  [2] HDREXDIE — HDR Exit Pattern Detection Interrupt Enable
    values as BIE.HDREXDIE
  [1] SPCNDDIE — STOP Condition Detection Interrupt Enable
    values as BIE.SPCNDDIE
  [0] STCNDDIE — START Condition Detection Interrupt Enable
    values as BIE.STCNDDIE
0x1D8 BIE_BY_LL 8-bit — Bus Interrupt Enable Register
  [7:5] Reserved — These bits are read as 000. The write value should be 000.
  [4] NACKDIE — NACK Detection Interrupt Enable
    values as BIE.NACKDIE
  [3] Reserved — This bit is read as 0. The write value should be 0.
  [2] HDREXDIE — HDR Exit Pattern Detection Interrupt Enable
    values as BIE.HDREXDIE
  [1] SPCNDDIE — STOP Condition Detection Interrupt Enable
    values as BIE.SPCNDDIE
  [0] STCNDDIE — START Condition Detection Interrupt Enable
    values as BIE.STCNDDIE
0x1D9 BIE_BY_LH 8-bit — Bus Interrupt Enable Register
  [7:1] Reserved — These bits are read as 0000000. The write value should be 0000000.
  [0] TENDIE — Transmit End Interrupt Enable
    values as BIE.TENDIE
0x1DA BIE_HA_H 16-bit — Bus Interrupt Enable Register
  [15:9] Reserved — These bits are read as 0000000. The write value should be 0000000.
  [8] WUCNDDIE — Wake-Up Condition Detection Interrupt Enable
    values as BIE.WUCNDDIE
  [7:5] Reserved — These bits are read as 000. The write value should be 000.
  [4] TODIE — Timeout Detection Interrupt Enable
    values as BIE.TODIE
  [3:1] Reserved — These bits are read as 000. The write value should be 000.
  [0] ALIE — Arbitration Lost Interrupt Enable
    values as BIE.ALIE
0x1DA BIE_BY_HL 8-bit — Bus Interrupt Enable Register
  [7:5] Reserved — These bits are read as 000. The write value should be 000.
  [4] TODIE — Timeout Detection Interrupt Enable
    values as BIE.TODIE
  [3:1] Reserved — These bits are read as 000. The write value should be 000.
  [0] ALIE — Arbitration Lost Interrupt Enable
    values as BIE.ALIE
0x1DB BIE_BY_HH 8-bit — Bus Interrupt Enable Register
  [7:1] Reserved — These bits are read as 0000000. The write value should be 0000000.
  [0] WUCNDDIE — Wake-Up Condition Detection Interrupt Enable
    values as BIE.WUCNDDIE
0x1DC BSTFC wo — Bus Status Force Register
  [31:25] Reserved — The write value should be 0000000.
  [24] WUCNDDFC — Wake-Up Condition Detection Force
    0=not Force Wake-Up Condition Detection Interrupt for software testing; 1=Force Wake-Up Condition Detection Interrupt for software testing
  [23:21] Reserved — The write value should be 000.
  [20] TODFC — Timeout Detection Force
    0=not Force Timeout Detection Interrupt for software testing; 1=Force Timeout Detection Interrupt for software testing
  [19:17] Reserved — The write value should be 000.
  [16] ALFC — Arbitration Lost Force
    0=not Force Arbitration Lost Interrupt for software testing; 1=Force Arbitration Lost Interrupt for software testing
  [15:9] Reserved — The write value should be 0000000.
  [8] TENDFC — Transmit End Force
    0=not Force Transmit End Interrupt for software testing; 1=Force Transmit End Interrupt for software testing
  [7:5] Reserved — The write value should be 000.
  [4] NACKDFC — NACK Detection Force
    0=not Force NACK Detection Interrupt for software testing; 1=Force NACK Detection Interrupt for software testing
  [3] Reserved — The write value should be 0.
  [2] HDREXDFC — HDR Exit Pattern Detection Force
    0=not Force HDR Exit Pattern Detection Interrupt for software testing; 1=Force HDR Exit Pattern Detection Interrupt for software testing
  [1] SPCNDDFC — STOP Condition Detection Force
    0=not Force STOP Condition Detection Interrupt for software testing; 1=Force STOP Condition Detection Interrupt for software testing
  [0] STCNDDFC — START Condition Detection Force
    0=not Force START Condition Detection Interrupt for software testing; 1=Force START Condition Detection Interrupt for software testing
0x1DC BSTFC_HA_L 16-bit wo — Bus Status Force Register
  [15:9] Reserved — The write value should be 0000000.
  [8] TENDFC — Transmit End Force
    values as BSTFC.TENDFC
  [7:5] Reserved — The write value should be 000.
  [4] NACKDFC — NACK Detection Force
    values as BSTFC.NACKDFC
  [3] Reserved — The write value should be 0.
  [2] HDREXDFC — HDR Exit Pattern Detection Force
    values as BSTFC.HDREXDFC
  [1] SPCNDDFC — STOP Condition Detection Force
    values as BSTFC.SPCNDDFC
  [0] STCNDDFC — START Condition Detection Force
    values as BSTFC.STCNDDFC
0x1DC BSTFC_BY_LL 8-bit wo — Bus Status Force Register
  [7:5] Reserved — The write value should be 000.
  [4] NACKDFC — NACK Detection Force
    values as BSTFC.NACKDFC
  [3] Reserved — The write value should be 0.
  [2] HDREXDFC — HDR Exit Pattern Detection Force
    values as BSTFC.HDREXDFC
  [1] SPCNDDFC — STOP Condition Detection Force
    values as BSTFC.SPCNDDFC
  [0] STCNDDFC — START Condition Detection Force
    values as BSTFC.STCNDDFC
0x1DD BSTFC_BY_LH 8-bit wo — Bus Status Force Register
  [7:1] Reserved — The write value should be 0000000.
  [0] TENDFC — Transmit End Force
    values as BSTFC.TENDFC
